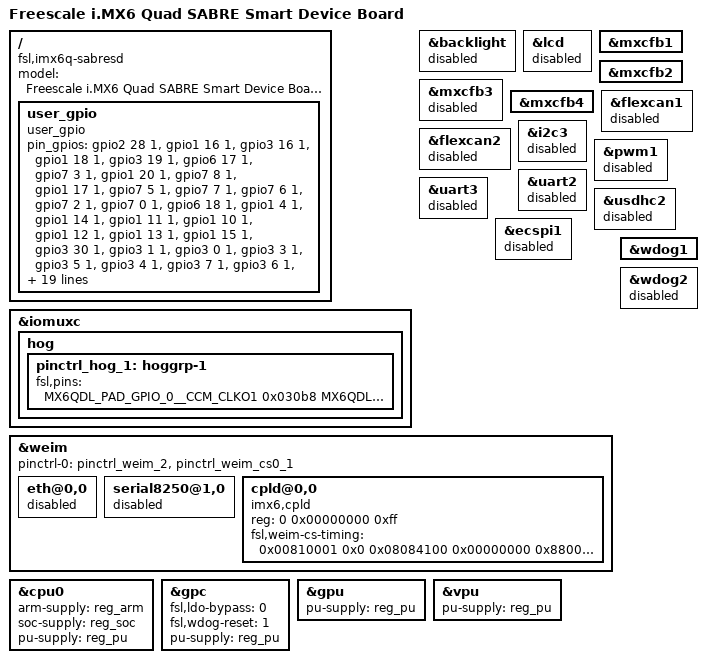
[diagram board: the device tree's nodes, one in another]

/dts-v1/;

#include "imx6q.dtsi"
#include "imx6qdl-sabresd.dtsi"

/ {
	model = "Freescale i.MX6 Quad SABRE Smart Device Board";
	compatible = "fsl,imx6q-sabresd", "fsl,imx6q";
	user_gpio {
        	compatible = "user_gpio";
//		pinctrl-0 = <&pinctrl_user_gpio1>;
        	pin_gpios = <
                	&gpio2 28 1
                	&gpio1 16 1
                	&gpio3 16 1
                	&gpio1 18 1
                	&gpio3 19 1
                	&gpio6 17 1
                	&gpio7 3 1
                	&gpio1 20 1
                	&gpio7 8 1
			&gpio1 17 1
                	&gpio7 5 1
                	&gpio7 7 1
                	&gpio7 6 1
                        &gpio7 2 1
                        &gpio7 0 1
                        &gpio6 18 1
			&gpio1 4 1
			&gpio1 14 1
			&gpio1 11 1
			&gpio1 10 1
			&gpio1 12 1
			&gpio1 13 1
			&gpio1 15 1
			&gpio3 30 1
			&gpio3 1 1
			&gpio3 0 1
			&gpio3 3 1
			&gpio3 5 1
			&gpio3 4 1
			&gpio3 7 1
			&gpio3 6 1
			&gpio3 9 1
			&gpio3 8 1
			&gpio3 11 1
			&gpio3 10 1
			&gpio3 15 1
			&gpio3 14 1
			&gpio5 0 1
			&gpio6 31 1
			&gpio7 4 1
			&gpio7 1 1
			&gpio3 13 1
			&gpio3 12 1
			&gpio2 24 1
			&gpio2 29 1
			&gpio3 18 1
			&gpio2 27 1
			&gpio3 17 1
			&gpio4 26 1
			&gpio4 25 1
			&gpio4 28 1
			&gpio4 27 1
			&gpio4 30 1
			&gpio4 29 1
			&gpio5 5 1
			&gpio4 31 1
			&gpio5 7 1
			&gpio5 6 1
			&gpio5 9 1
			&gpio5 8 1
			&gpio5 13 1
			&gpio5 12 1
			&gpio5 15 1
			&gpio5 14 1
			&gpio5 17 1
			&gpio5 16 1
			&gpio4 20 1
			&gpio1 21 1
			&gpio5 11 1
			&gpio5 10 1
			&gpio4 15 1
			&gpio1 7 1
			&gpio4 14 1
			&gpio1 8 1
			&gpio1 6 1
			&gpio1 5 1
			&gpio4 23 1
			&gpio4 24 1
			&gpio4 21 1
			&gpio4 22 1
			&gpio4 19 1
			&gpio4 18 1
			&gpio4 17 1
			&gpio3 26 1
			&gpio4 16 1
			&gpio3 27 1
			&gpio3 25 1
			&gpio3 24 1
			&gpio5 19 1
			&gpio5 18 1
			&gpio1 3 1
			 >;
	};
};


&iomuxc {
	hog {
		pinctrl_hog_1: hoggrp-1 {
			fsl,pins = <
				MX6QDL_PAD_GPIO_0__CCM_CLKO1    0x030b8
				MX6QDL_PAD_EIM_EB0__GPIO2_IO28  0x80000000
				MX6QDL_PAD_SD1_DAT0__GPIO1_IO16 0x80000000
				MX6QDL_PAD_EIM_D16__GPIO3_IO16 0x80000000
				MX6QDL_PAD_SD1_CMD__GPIO1_IO18 0x80000000
				MX6QDL_PAD_EIM_D19__GPIO3_IO19 0x80000000
				MX6QDL_PAD_SD3_DAT7__GPIO6_IO17 0x80000000
				MX6QDL_PAD_SD3_CLK__GPIO7_IO03 0x80000000
				MX6QDL_PAD_SD1_CLK__GPIO1_IO20 0x80000000
				MX6QDL_PAD_SD3_RST__GPIO7_IO08 0x80000000
				MX6QDL_PAD_SD1_DAT1__GPIO1_IO17 0x80000000
				MX6QDL_PAD_SD3_DAT1__GPIO7_IO05 0x80000000
				MX6QDL_PAD_SD3_DAT3__GPIO7_IO07 0x80000000
				MX6QDL_PAD_SD3_DAT2__GPIO7_IO06 0x80000000
				MX6QDL_PAD_SD3_CMD__GPIO7_IO02 0x80000000
				MX6QDL_PAD_SD3_DAT5__GPIO7_IO00 0x80000000
				MX6QDL_PAD_SD3_DAT6__GPIO6_IO18 0x80000000
				MX6QDL_PAD_GPIO_4__GPIO1_IO04 0x80000000
				MX6QDL_PAD_SD2_DAT1__GPIO1_IO14 0x80000000
				MX6QDL_PAD_SD2_CMD__GPIO1_IO11 0x80000000
				MX6QDL_PAD_SD2_CLK__GPIO1_IO10 0x80000000
				MX6QDL_PAD_SD2_DAT3__GPIO1_IO12 0x80000000
				MX6QDL_PAD_SD2_DAT2__GPIO1_IO13 0x80000000
				MX6QDL_PAD_SD2_DAT0__GPIO1_IO15 0x80000000
				MX6QDL_PAD_EIM_D30__GPIO3_IO30 0x80000000
				MX6QDL_PAD_EIM_DA1__GPIO3_IO01 0x80000000
				MX6QDL_PAD_EIM_DA0__GPIO3_IO00 0x80000000
				MX6QDL_PAD_EIM_DA3__GPIO3_IO03 0x80000000
				MX6QDL_PAD_EIM_DA5__GPIO3_IO05 0x80000000
				MX6QDL_PAD_EIM_DA4__GPIO3_IO04 0x80000000
				MX6QDL_PAD_EIM_DA7__GPIO3_IO07 0x80000000
				MX6QDL_PAD_EIM_DA6__GPIO3_IO06 0x80000000
				MX6QDL_PAD_EIM_DA9__GPIO3_IO09 0x80000000
				MX6QDL_PAD_EIM_DA8__GPIO3_IO08 0x80000000
				MX6QDL_PAD_EIM_DA11__GPIO3_IO11 0x80000000
				MX6QDL_PAD_EIM_DA10__GPIO3_IO10 0x80000000
				MX6QDL_PAD_EIM_DA15__GPIO3_IO15 0x80000000
				MX6QDL_PAD_EIM_DA14__GPIO3_IO14 0x80000000
				MX6QDL_PAD_EIM_WAIT__GPIO5_IO00 0x80000000
				MX6QDL_PAD_EIM_BCLK__GPIO6_IO31 0x80000000
				MX6QDL_PAD_SD3_DAT0__GPIO7_IO04 0x80000000
				MX6QDL_PAD_SD3_DAT4__GPIO7_IO01 0x80000000
				MX6QDL_PAD_EIM_DA13__GPIO3_IO13 0x80000000
				MX6QDL_PAD_EIM_DA12__GPIO3_IO12 0x80000000
				MX6QDL_PAD_EIM_CS1__GPIO2_IO24 0x80000000
				MX6QDL_PAD_EIM_EB1__GPIO2_IO29 0x80000000
				MX6QDL_PAD_EIM_D18__GPIO3_IO18 0x80000000
				MX6QDL_PAD_EIM_LBA__GPIO2_IO27 0x80000000
				MX6QDL_PAD_EIM_D17__GPIO3_IO17 0x80000000
				MX6QDL_PAD_DISP0_DAT5__GPIO4_IO26 0x80000000
				MX6QDL_PAD_DISP0_DAT4__GPIO4_IO25 0x80000000
				MX6QDL_PAD_DISP0_DAT7__GPIO4_IO28 0x80000000
				MX6QDL_PAD_DISP0_DAT6__GPIO4_IO27 0x80000000
				MX6QDL_PAD_DISP0_DAT9__GPIO4_IO30 0x80000000
				MX6QDL_PAD_DISP0_DAT8__GPIO4_IO29 0x80000000
				MX6QDL_PAD_DISP0_DAT11__GPIO5_IO05 0x80000000
				MX6QDL_PAD_DISP0_DAT10__GPIO4_IO31 0x80000000
				MX6QDL_PAD_DISP0_DAT13__GPIO5_IO07 0x80000000
				MX6QDL_PAD_DISP0_DAT12__GPIO5_IO06 0x80000000
				MX6QDL_PAD_DISP0_DAT15__GPIO5_IO09 0x80000000
				MX6QDL_PAD_DISP0_DAT14__GPIO5_IO08 0x80000000
				MX6QDL_PAD_DISP0_DAT19__GPIO5_IO13 0x80000000
				MX6QDL_PAD_DISP0_DAT18__GPIO5_IO12 0x80000000
				MX6QDL_PAD_DISP0_DAT21__GPIO5_IO15 0x80000000
				MX6QDL_PAD_DISP0_DAT20__GPIO5_IO14 0x80000000
				MX6QDL_PAD_DISP0_DAT23__GPIO5_IO17 0x80000000
				MX6QDL_PAD_DISP0_DAT22__GPIO5_IO16 0x80000000
				MX6QDL_PAD_DI0_PIN4__GPIO4_IO20 0x80000000
				MX6QDL_PAD_SD1_DAT3__GPIO1_IO21 0x80000000
				MX6QDL_PAD_DISP0_DAT17__GPIO5_IO11 0x80000000
				MX6QDL_PAD_DISP0_DAT16__GPIO5_IO10 0x80000000
				MX6QDL_PAD_KEY_ROW4__GPIO4_IO15 0x80000000
				MX6QDL_PAD_GPIO_7__GPIO1_IO07 0x80000000
				MX6QDL_PAD_GPIO_8__GPIO1_IO08 0x80000000
				MX6QDL_PAD_GPIO_6__GPIO1_IO06 0x80000000
				MX6QDL_PAD_GPIO_5__GPIO1_IO05 0x80000000
				MX6QDL_PAD_DISP0_DAT2__GPIO4_IO23 0x80000000
				MX6QDL_PAD_DISP0_DAT3__GPIO4_IO24 0x80000000
				MX6QDL_PAD_DISP0_DAT0__GPIO4_IO21 0x80000000
				MX6QDL_PAD_DISP0_DAT1__GPIO4_IO22 0x80000000
				MX6QDL_PAD_DI0_PIN3__GPIO4_IO19 0x80000000
				MX6QDL_PAD_DI0_PIN2__GPIO4_IO18 0x80000000
				MX6QDL_PAD_DI0_PIN15__GPIO4_IO17 0x80000000
				MX6QDL_PAD_EIM_D26__GPIO3_IO26 0x80000000
				MX6QDL_PAD_DI0_DISP_CLK__GPIO4_IO16 0x80000000
				MX6QDL_PAD_EIM_D27__GPIO3_IO27 0x80000000
				MX6QDL_PAD_EIM_D25__GPIO3_IO25 0x80000000
				MX6QDL_PAD_EIM_D24__GPIO3_IO24 0x80000000
				MX6QDL_PAD_CSI0_MCLK__GPIO5_IO19 0x80000000
				MX6QDL_PAD_CSI0_PIXCLK__GPIO5_IO18 0x80000000
				MX6QDL_PAD_GPIO_3__GPIO1_IO03 0x80000000
			>;
		};
	};
};
/*
&ldb {
	lvds-channel@0 {
		crtc = "ipu2-di0";
	};

	lvds-channel@1 {
		crtc = "ipu2-di1";
	};
};
*/

&backlight {
	status = "disabled";
};

&lcd {
	status = "disabled";
};

&mxcfb1 {
	status = "okay";
};

&mxcfb2 {
	status = "okay";
};

&mxcfb3 {
	status = "disabled";
};

&mxcfb4 {
	status = "okay";
};


&flexcan1 {
	status = "disabled";
};

&flexcan2 {
	status = "disabled";
};

&i2c3 {
	status = "disabled";
};

&pwm1 {
	status = "disabled";
};

&uart2 {
	status = "disabled";
};

&uart3 {
	status = "disabled";
};

&usdhc2 {
	status = "disabled";
};

 &ecspi1  {
	status = "disabled";
};

&weim {
	status = "okay";
	pinctrl-0 = <&pinctrl_weim_2 &pinctrl_weim_cs0_1>;
	eth@0,0 {
		status = "disabled";
	};

	serial8250@1,0 {
		status = "disabled";
	};
	cpld@0,0 {
		compatible = "imx6,cpld";
		reg = < 0 0x00000000 0xff>;
                fsl,weim-cs-timing = <0x00810001 0x0 0x08084100
                        0x00000000 0x88000800 0x00000000>;
		status = "okay";
	};
};

&cpu0 {
	arm-supply = <&reg_arm>;
	soc-supply = <&reg_soc>;
	pu-supply = <&reg_pu>; /* use pu_dummy if VDDSOC share with VDDPU */
};

&gpc {
	fsl,ldo-bypass = <0>; /* use ldo-bypass, u-boot will check it and configure */
	fsl,wdog-reset = <1>; /* watchdog select of reset source */
	pu-supply = <&reg_pu>; /* ldo-bypass:use pu_dummy if VDDSOC share with VDDPU */
};

&gpu {
	pu-supply = <&reg_pu>; /* ldo-bypass:use pu_dummy if VDDSOC share with VDDPU */
};

&vpu {
	pu-supply = <&reg_pu>; /* ldo-bypass:use pu_dummy if VDDSOC share with VDDPU */
};

&wdog1 {
	status = "okay";
};

&wdog2 {
	status = "disabled";
};

